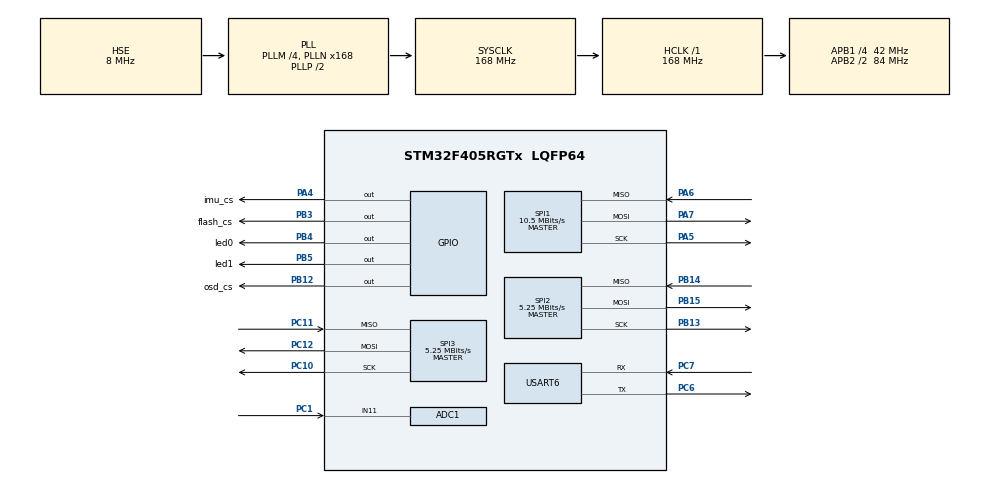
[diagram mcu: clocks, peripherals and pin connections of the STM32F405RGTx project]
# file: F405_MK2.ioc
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ADC1.Channel-0\#ChannelRegularConversion=ADC_CHANNEL_11
ADC1.NbrOfConversionFlag=1
ADC1.Rank-0\#ChannelRegularConversion=1
ADC1.SamplingTime-0\#ChannelRegularConversion=ADC_SAMPLETIME_3CYCLES
ADC1.master=1
Mcu.Family=STM32F4
Mcu.Name=STM32F405RGTx
Mcu.Package=LQFP64
NVIC.PriorityGroup=NVIC_PRIORITYGROUP_4
NVIC.USART6_IRQn=true\:0\:0\:false\:false\:true\:true\:true\:true
PA4.GPIO_Label=imu_cs
PA4.PinState=GPIO_PIN_SET
PA4.Signal=GPIO_Output
PA5.Mode=Full_Duplex_Master
PA5.Signal=SPI1_SCK
PA6.Mode=Full_Duplex_Master
PA6.Signal=SPI1_MISO
PA7.Mode=Full_Duplex_Master
PA7.Signal=SPI1_MOSI
PB12.GPIO_Label=osd_cs
PB12.PinState=GPIO_PIN_SET
PB12.Signal=GPIO_Output
PB13.Mode=Full_Duplex_Master
PB13.Signal=SPI2_SCK
PB14.Mode=Full_Duplex_Master
PB14.Signal=SPI2_MISO
PB15.Mode=Full_Duplex_Master
PB15.Signal=SPI2_MOSI
PB3.GPIO_Label=flash_cs
PB3.PinState=GPIO_PIN_SET
PB3.Signal=GPIO_Output
PB4.GPIO_Label=led0
PB4.Signal=GPIO_Output
PB5.GPIO_Label=led1
PB5.Signal=GPIO_Output
PC1.Signal=ADCx_IN11
PC10.Mode=Full_Duplex_Master
PC10.Signal=SPI3_SCK
PC11.Mode=Full_Duplex_Master
PC11.Signal=SPI3_MISO
PC12.Mode=Full_Duplex_Master
PC12.Signal=SPI3_MOSI
PC6.Mode=Asynchronous
PC6.Signal=USART6_TX
PC7.Mode=Asynchronous
PC7.Signal=USART6_RX
PH0-OSC_IN.Mode=HSE-External-Oscillator
PH0-OSC_IN.Signal=RCC_OSC_IN
PH1-OSC_OUT.Mode=HSE-External-Oscillator
PH1-OSC_OUT.Signal=RCC_OSC_OUT
ProjectManager.HeapSize=0x200
ProjectManager.StackSize=0x400
ProjectManager.TargetToolchain=MDK-ARM V5.32
RCC.48MHZClocksFreq_Value=84000000
RCC.AHBFreq_Value=168000000
RCC.APB1CLKDivider=RCC_HCLK_DIV4
RCC.APB1Freq_Value=42000000
RCC.APB1TimFreq_Value=84000000
RCC.APB2CLKDivider=RCC_HCLK_DIV2
RCC.APB2Freq_Value=84000000
RCC.APB2TimFreq_Value=168000000
RCC.CortexFreq_Value=168000000
RCC.HCLKFreq_Value=168000000
RCC.HSE_VALUE=8000000
RCC.HSI_VALUE=16000000
RCC.LSE_VALUE=32768
RCC.PLLM=4
RCC.PLLN=168
RCC.PLLSourceVirtual=RCC_PLLSOURCE_HSE
RCC.SYSCLKFreq_VALUE=168000000
RCC.SYSCLKSource=RCC_SYSCLKSOURCE_PLLCLK
RCC.VCOOutputFreq_Value=336000000
SH.ADCx_IN11.0=ADC1_IN11,IN11
SPI1.BaudRatePrescaler=SPI_BAUDRATEPRESCALER_8
SPI1.CalculateBaudRate=10.5 MBits/s
SPI1.Direction=SPI_DIRECTION_2LINES
SPI1.Mode=SPI_MODE_MASTER
SPI1.VirtualType=VM_MASTER
SPI2.BaudRatePrescaler=SPI_BAUDRATEPRESCALER_8
SPI2.CalculateBaudRate=5.25 MBits/s
SPI2.Direction=SPI_DIRECTION_2LINES
SPI2.Mode=SPI_MODE_MASTER
SPI2.VirtualType=VM_MASTER
SPI3.BaudRatePrescaler=SPI_BAUDRATEPRESCALER_8
SPI3.CalculateBaudRate=5.25 MBits/s
SPI3.Direction=SPI_DIRECTION_2LINES
SPI3.Mode=SPI_MODE_MASTER
SPI3.VirtualType=VM_MASTER
USART6.VirtualMode=VM_ASYNC
board=custom

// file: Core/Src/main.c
/* USER CODE BEGIN Header */
/**
  ******************************************************************************
  * @file           : main.c
  * @brief          : Main program body
  ******************************************************************************
  * @attention
  *
  * Copyright (c) 2023 STMicroelectronics.
  * All rights reserved.
  *
  * This software is licensed under terms that can be found in the LICENSE file
  * in the root directory of this software component.
  * If no LICENSE file comes with this software, it is provided AS-IS.
  *
  ******************************************************************************
  */
/* USER CODE END Header */
#include "main.h"
#include "adc.h"
#include "spi.h"
#include "usart.h"
#include "gpio.h"

/* USER CODE BEGIN Includes */
#include "icm426xx.h"
#include "w25qxxx.h"
#include "max7456.h"
#include "public.h"
/* USER CODE END Includes */

void SystemClock_Config(void);

int main(void)
{
  /* USER CODE BEGIN 1 */
	uint32_t count=0;
  /* USER CODE END 1 */

  /* MCU Configuration--------------------------------------------------------*/

  /* Reset of all peripherals, Initializes the Flash interface and the Systick. */
  HAL_Init();

  /* Configure the system clock */
  SystemClock_Config();

  /* Initialize all configured peripherals */
  MX_GPIO_Init();
  MX_ADC1_Init();
  MX_SPI1_Init();
  MX_SPI2_Init();
  MX_SPI3_Init();
  MX_USART6_UART_Init();

  /* USER CODE BEGIN 2 */
	max7456Init();
	Icm42688Init();
	spiflash_test();
  /* USER CODE END 2 */

  /* Infinite loop */
  while (1)
  {

    /* USER CODE BEGIN 3 */
	  decode_MCB_communication_data();

		count++;
		if(count>=2000000)
		{
			//printf(" UART TEST\r\n");
			count=0;
			HAL_GPIO_TogglePin(GPIOB, led0_Pin|led1_Pin);
		}
  }
  /* USER CODE END 3 */
}

void SystemClock_Config(void)
{
  RCC_OscInitTypeDef RCC_OscInitStruct = {0};
  RCC_ClkInitTypeDef RCC_ClkInitStruct = {0};

  /** Configure the main internal regulator output voltage
  */
  __HAL_RCC_PWR_CLK_ENABLE();
  __HAL_PWR_VOLTAGESCALING_CONFIG(PWR_REGULATOR_VOLTAGE_SCALE1);

  /** Initializes the RCC Oscillators according to the specified parameters
  * in the RCC_OscInitTypeDef structure.
  */
  RCC_OscInitStruct.OscillatorType = RCC_OSCILLATORTYPE_HSE;
  RCC_OscInitStruct.HSEState = RCC_HSE_ON;
  RCC_OscInitStruct.PLL.PLLState = RCC_PLL_ON;
  RCC_OscInitStruct.PLL.PLLSource = RCC_PLLSOURCE_HSE;
  RCC_OscInitStruct.PLL.PLLM = 4;
  RCC_OscInitStruct.PLL.PLLN = 168;
  RCC_OscInitStruct.PLL.PLLP = RCC_PLLP_DIV2;
  RCC_OscInitStruct.PLL.PLLQ = 4;
  if (HAL_RCC_OscConfig(&RCC_OscInitStruct) != HAL_OK)
  {
    Error_Handler();
  }

  /** Initializes the CPU, AHB and APB buses clocks
  */
  RCC_ClkInitStruct.ClockType = RCC_CLOCKTYPE_HCLK|RCC_CLOCKTYPE_SYSCLK
                              |RCC_CLOCKTYPE_PCLK1|RCC_CLOCKTYPE_PCLK2;
  RCC_ClkInitStruct.SYSCLKSource = RCC_SYSCLKSOURCE_PLLCLK;
  RCC_ClkInitStruct.AHBCLKDivider = RCC_SYSCLK_DIV1;
  RCC_ClkInitStruct.APB1CLKDivider = RCC_HCLK_DIV4;
  RCC_ClkInitStruct.APB2CLKDivider = RCC_HCLK_DIV2;

  if (HAL_RCC_ClockConfig(&RCC_ClkInitStruct, FLASH_LATENCY_5) != HAL_OK)
  {
    Error_Handler();
  }
}

void Error_Handler(void)
{
  __disable_irq();
  while (1)
  {
  }
}
